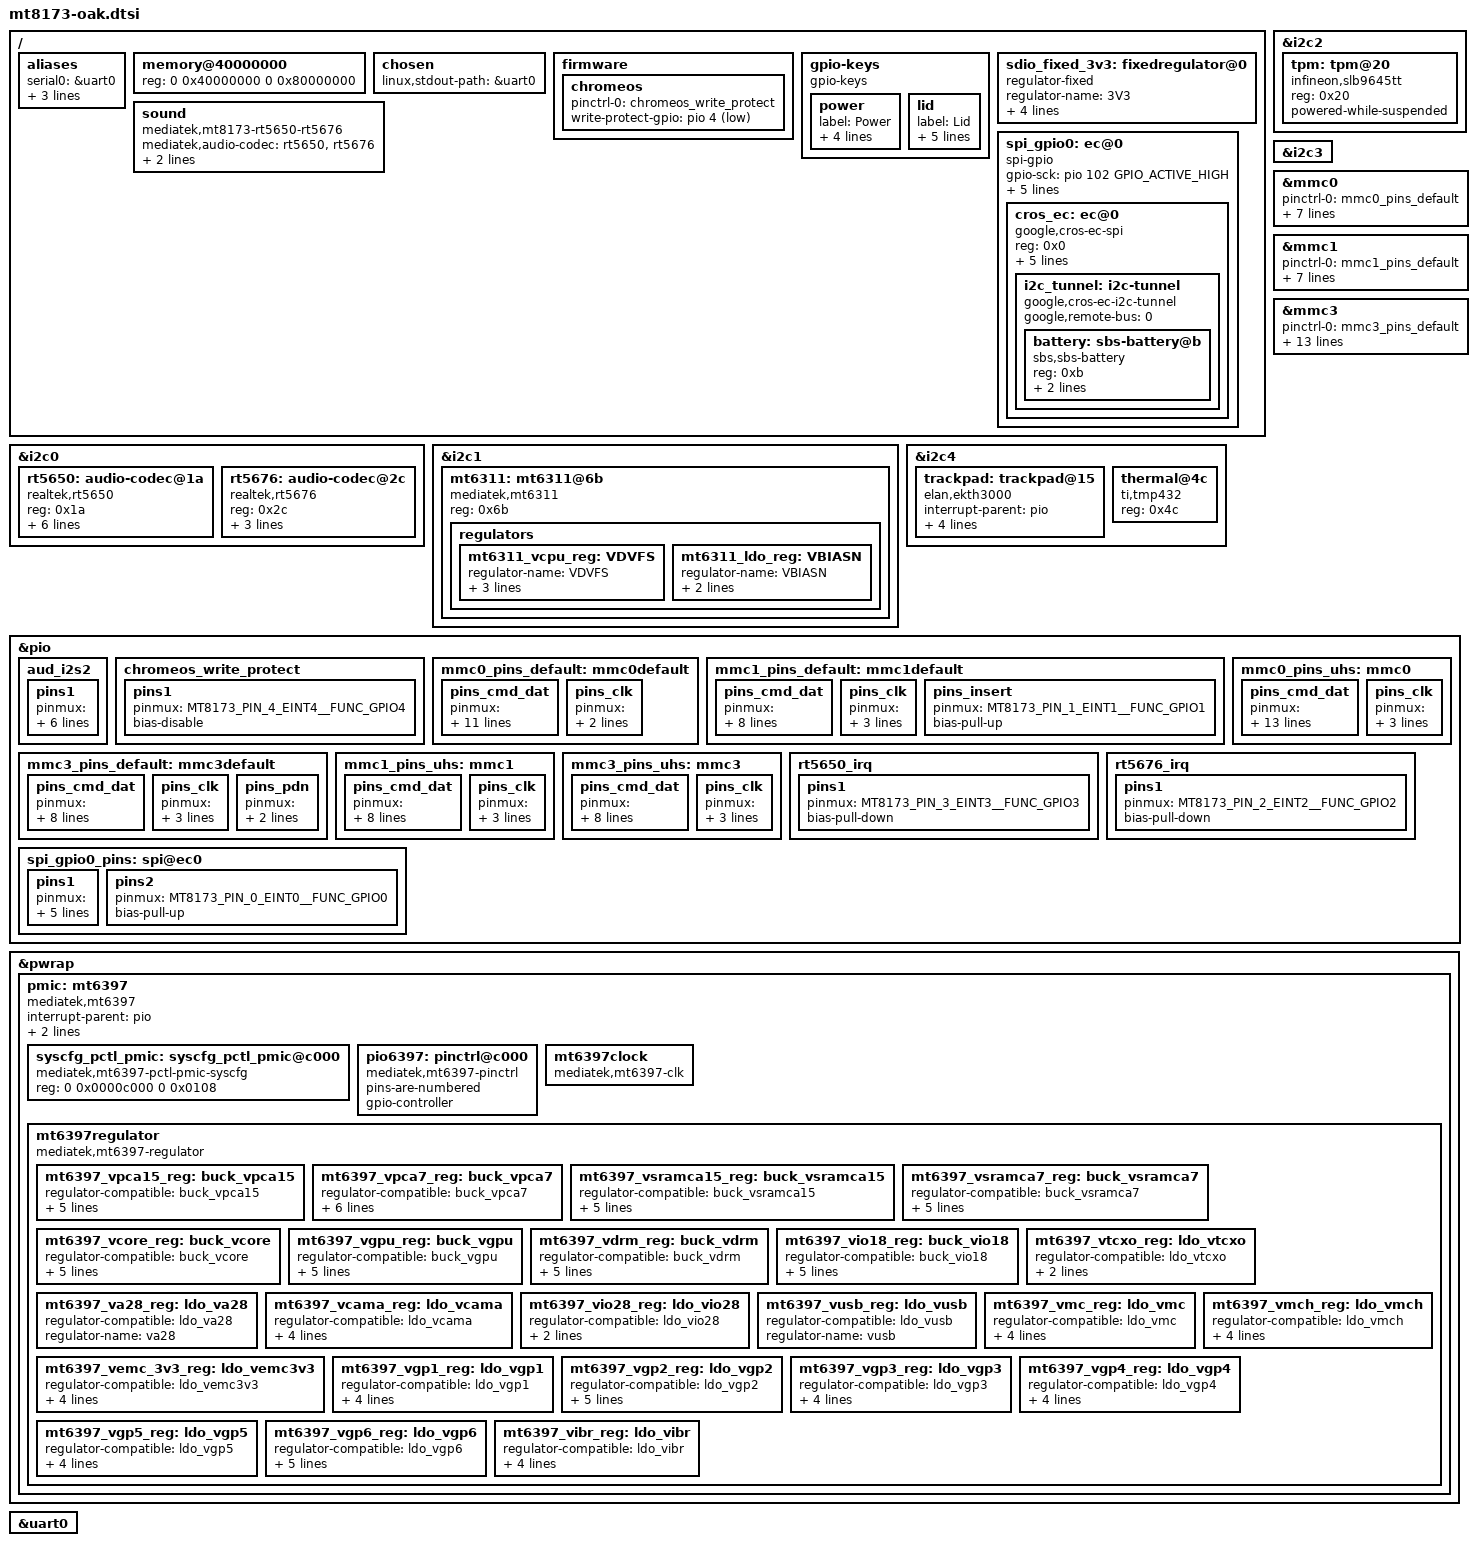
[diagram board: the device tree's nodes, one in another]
/*
 * This program is free software; you can redistribute it and/or modify
 * it under the terms of the GNU General Public License version 2 as
 * published by the Free Software Foundation.
 *
 * This program is distributed in the hope that it will be useful,
 * but WITHOUT ANY WARRANTY; without even the implied warranty of
 * MERCHANTABILITY or FITNESS FOR A PARTICULAR PURPOSE.  See the
 * GNU General Public License for more details.
 */

#include <dt-bindings/input/input.h>
#include <dt-bindings/gpio/gpio.h>
#include "mt8173.dtsi"
#include "mt8173-pinfunc.h"

/ {
	aliases {
		serial0 = &uart0;
		serial1 = &uart1;
		serial2 = &uart2;
		serial3 = &uart3;
	};

	memory@40000000 {
		device_type = "memory";
		reg = <0 0x40000000 0 0x80000000>;
	};

	chosen {
		linux,stdout-path = &uart0;
	};

	firmware {
		chromeos {
			pinctrl-names = "default";
			pinctrl-0 = <&chromeos_write_protect>;
			write-protect-gpio = <&pio 4 GPIO_ACTIVE_LOW>;
		};
	};

	gpio-keys {
		compatible = "gpio-keys";

		power {
			label = "Power";
			gpios = <&pio 14 GPIO_ACTIVE_HIGH>;
			linux,code = <KEY_POWER>;
			debounce-interval = <1>;
			gpio-key,wakeup;
		};

		lid {
			label = "Lid";
			gpios = <&pio 12 GPIO_ACTIVE_LOW>;
			linux,code = <0>; /* SW_LID */
			linux,input-type = <5>; /* EV_SW */
			debounce-interval = <1>;
			gpio-key,wakeup;
		};
	};

	sdio_fixed_3v3: fixedregulator@0 {
		compatible = "regulator-fixed";
		regulator-name = "3V3";
		regulator-min-microvolt = <3300000>;
		regulator-max-microvolt = <3300000>;
		gpio = <&pio 100 0>;
		enable-active-high;
	};

	sound {
		compatible = "mediatek,mt8173-rt5650-rt5676";
		mediatek,audio-codec = <&rt5650 &rt5676>;
		mediatek,platform = <&afe>;
		pinctrl-names = "default";
		pinctrl-0 = <&aud_i2s2>;
	};

	spi_gpio0: ec@0 {
		compatible = "spi-gpio";
		#address-cells = <0x1>;
		#size-cells = <0>;
		gpio-sck = <&pio 102 GPIO_ACTIVE_HIGH>;
		gpio-miso = <&pio 103 GPIO_ACTIVE_HIGH>;
		gpio-mosi = <&pio 104 GPIO_ACTIVE_HIGH>;
		cs-gpios = <&pio 105 GPIO_ACTIVE_HIGH>;
		num-chipselects = <1>;
		pinctrl-names = "default";
		pinctrl-0 = <&spi_gpio0_pins>;
		status = "okay";

		cros_ec: ec@0 {
			compatible = "google,cros-ec-spi";
			reg = <0x0>;
			spi-max-frequency = <18000000>;
			interrupt-parent = <&pio>;
			interrupts = <0 IRQ_TYPE_LEVEL_LOW>;
			google,cros-ec-spi-msg-delay = <500>;
			google,cros-ec-spi-pre-delay = <500>;

			i2c_tunnel: i2c-tunnel {
				compatible = "google,cros-ec-i2c-tunnel";
				google,remote-bus = <0>;
				#address-cells = <1>;
				#size-cells = <0>;
			};
		};
	};
};

&i2c0 {
	status = "okay";

	rt5650: audio-codec@1a {
		compatible = "realtek,rt5650";
		reg = <0x1a>;
		avdd-supply = <&mt6397_vgp1_reg>;
		cpvdd-supply = <&mt6397_vcama_reg>;
		interrupt-parent = <&pio>;
		interrupts = <3 IRQ_TYPE_EDGE_BOTH>;
		pinctrl-names = "default";
		pinctrl-0 = <&rt5650_irq>;
		realtek,jd-mode = <3>;
	};

	rt5676: audio-codec@2c {
		compatible = "realtek,rt5676";
		reg = <0x2c>;
		interrupt-parent = <&pio>;
		interrupts = <2 IRQ_TYPE_EDGE_BOTH>;
		pinctrl-names = "default";
		pinctrl-0 = <&rt5676_irq>;
	};
};

&i2c1 {
	status = "okay";

	mt6311: mt6311@6b {
		compatible = "mediatek,mt6311";
		reg = <0x6b>;

		regulators {
			mt6311_vcpu_reg: VDVFS {
				regulator-name = "VDVFS";
				regulator-min-microvolt = < 600000>;
				regulator-max-microvolt = <1400000>;
				regulator-ramp-delay = <10000>;
			};
			mt6311_ldo_reg: VBIASN {
				regulator-name = "VBIASN";
				regulator-min-microvolt = <200000>;
				regulator-max-microvolt = <800000>;
			};
		};
	};
};

&i2c2 {
	status = "okay";

	tpm: tpm@20 {
		compatible = "infineon,slb9645tt";
		reg = <0x20>;
		powered-while-suspended;
	};
};

&i2c3 {
	status = "okay";
};

&i2c4 {
	status = "okay";

	trackpad: trackpad@15 {
		compatible = "elan,ekth3000";
		interrupt-parent = <&pio>;
		interrupts = <124 IRQ_TYPE_LEVEL_LOW>;
		reg = <0x15>;
		vcc-supply = <&mt6397_vgp6_reg>;
		wakeup-source;
	};

	thermal@4c {
		compatible = "ti,tmp432";
		reg = <0x4c>;
	};
};

&i2c_tunnel {
	battery: sbs-battery@b {
		compatible = "sbs,sbs-battery";
		reg = <0xb>;
		sbs,i2c-retry-count = <2>;
		sbs,poll-retry-count = <1>;
	};
};

&mmc0 {
	status = "okay";
	pinctrl-names = "default", "state_uhs";
	pinctrl-0 = <&mmc0_pins_default>;
	pinctrl-1 = <&mmc0_pins_uhs>;
	bus-width = <8>;
	max-frequency = <50000000>;
	cap-mmc-highspeed;
	vmmc-supply = <&mt6397_vemc_3v3_reg>;
	vqmmc-supply = <&mt6397_vio18_reg>;
	non-removable;
};

&mmc1 {
	status = "okay";
	pinctrl-names = "default", "state_uhs";
	pinctrl-0 = <&mmc1_pins_default>;
	pinctrl-1 = <&mmc1_pins_uhs>;
	bus-width = <4>;
	max-frequency = <25000000>;
	cap-sd-highspeed;
	cd-gpios = <&pio 1 GPIO_ACTIVE_HIGH>;
	vmmc-supply = <&mt6397_vmch_reg>;
	vqmmc-supply = <&mt6397_vmc_reg>;
};

&mmc3 {
	status = "okay";
	pinctrl-names = "default", "state_uhs";
	pinctrl-0 = <&mmc3_pins_default>;
	pinctrl-1 = <&mmc3_pins_uhs>;
	bus-width = <4>;
	max-frequency = <25000000>;
	cap-sd-highspeed;
	sd-uhs-sdr12;
	sd-uhs-sdr25;
	sd-uhs-sdr50;
	sd-uhs-sdr104;
	keep-power-in-suspend;
	enable-sdio-wakeup;
	vmmc-supply = <&sdio_fixed_3v3>;
	vqmmc-supply = <&mt6397_vgp3_reg>;
	non-removable;
};

&pio {
	aud_i2s2: aud_i2s2 {
		pins1 {
			pinmux = <MT8173_PIN_128_I2S0_LRCK__FUNC_I2S1_WS>,
				 <MT8173_PIN_129_I2S0_BCK__FUNC_I2S1_BCK>,
				 <MT8173_PIN_130_I2S0_MCK__FUNC_I2S1_MCK>,
				 <MT8173_PIN_131_I2S0_DATA0__FUNC_I2S1_DO_1>,
				 <MT8173_PIN_132_I2S0_DATA1__FUNC_I2S2_DI_2>;
			bias-pull-down;
		};
	};

	chromeos_write_protect: chromeos_write_protect {
		pins1 {
			pinmux = <MT8173_PIN_4_EINT4__FUNC_GPIO4>;
			bias-disable;
		};
	};

	mmc0_pins_default: mmc0default {
		pins_cmd_dat {
			pinmux = <MT8173_PIN_57_MSDC0_DAT0__FUNC_MSDC0_DAT0>,
				 <MT8173_PIN_58_MSDC0_DAT1__FUNC_MSDC0_DAT1>,
				 <MT8173_PIN_59_MSDC0_DAT2__FUNC_MSDC0_DAT2>,
				 <MT8173_PIN_60_MSDC0_DAT3__FUNC_MSDC0_DAT3>,
				 <MT8173_PIN_61_MSDC0_DAT4__FUNC_MSDC0_DAT4>,
				 <MT8173_PIN_62_MSDC0_DAT5__FUNC_MSDC0_DAT5>,
				 <MT8173_PIN_63_MSDC0_DAT6__FUNC_MSDC0_DAT6>,
				 <MT8173_PIN_64_MSDC0_DAT7__FUNC_MSDC0_DAT7>,
				 <MT8173_PIN_66_MSDC0_CMD__FUNC_MSDC0_CMD>,
				 <MT8173_PIN_68_MSDC0_RST___FUNC_MSDC0_RSTB>;
				bias-pull-up;
		};

		pins_clk {
			pinmux = <MT8173_PIN_65_MSDC0_CLK__FUNC_MSDC0_CLK>;
				bias-pull-down;
		};
	};

	mmc1_pins_default: mmc1default {
		pins_cmd_dat {
			pinmux = <MT8173_PIN_73_MSDC1_DAT0__FUNC_MSDC1_DAT0>,
				 <MT8173_PIN_74_MSDC1_DAT1__FUNC_MSDC1_DAT1>,
				 <MT8173_PIN_75_MSDC1_DAT2__FUNC_MSDC1_DAT2>,
				 <MT8173_PIN_76_MSDC1_DAT3__FUNC_MSDC1_DAT3>,
				 <MT8173_PIN_78_MSDC1_CMD__FUNC_MSDC1_CMD>;
			input-enable;
			drive-strength = <MTK_DRIVE_4mA>;
			bias-pull-up = <MTK_PUPD_SET_R1R0_10>;
		};

		pins_clk {
			pinmux = <MT8173_PIN_77_MSDC1_CLK__FUNC_MSDC1_CLK>;
			bias-pull-down;
			drive-strength = <MTK_DRIVE_4mA>;
		};

		pins_insert {
			pinmux = <MT8173_PIN_1_EINT1__FUNC_GPIO1>;
			bias-pull-up;
		};
	};

	mmc3_pins_default: mmc3default {
		pins_cmd_dat {
			pinmux = <MT8173_PIN_22_MSDC3_DAT0__FUNC_MSDC3_DAT0>,
				 <MT8173_PIN_23_MSDC3_DAT1__FUNC_MSDC3_DAT1>,
				 <MT8173_PIN_24_MSDC3_DAT2__FUNC_MSDC3_DAT2>,
				 <MT8173_PIN_25_MSDC3_DAT3__FUNC_MSDC3_DAT3>,
				 <MT8173_PIN_27_MSDC3_CMD__FUNC_MSDC3_CMD>;
			input-enable;
			drive-strength = <MTK_DRIVE_4mA>;
			bias-pull-up = <MTK_PUPD_SET_R1R0_10>;
		};

		pins_clk {
			pinmux = <MT8173_PIN_26_MSDC3_CLK__FUNC_MSDC3_CLK>;
			bias-pull-down;
			drive-strength = <MTK_DRIVE_4mA>;
		};

		pins_pdn {
			pinmux = <MT8173_PIN_100_MSDC2_DAT0__FUNC_GPIO100>;
			output-high;
		};
	};

	mmc0_pins_uhs: mmc0 {
		pins_cmd_dat {
			pinmux = <MT8173_PIN_57_MSDC0_DAT0__FUNC_MSDC0_DAT0>,
				 <MT8173_PIN_58_MSDC0_DAT1__FUNC_MSDC0_DAT1>,
				 <MT8173_PIN_59_MSDC0_DAT2__FUNC_MSDC0_DAT2>,
				 <MT8173_PIN_60_MSDC0_DAT3__FUNC_MSDC0_DAT3>,
				 <MT8173_PIN_61_MSDC0_DAT4__FUNC_MSDC0_DAT4>,
				 <MT8173_PIN_62_MSDC0_DAT5__FUNC_MSDC0_DAT5>,
				 <MT8173_PIN_63_MSDC0_DAT6__FUNC_MSDC0_DAT6>,
				 <MT8173_PIN_64_MSDC0_DAT7__FUNC_MSDC0_DAT7>,
				 <MT8173_PIN_68_MSDC0_RST___FUNC_MSDC0_RSTB>,
				 <MT8173_PIN_66_MSDC0_CMD__FUNC_MSDC0_CMD>;
			input-enable;
			drive-strength = <MTK_DRIVE_2mA>;
			bias-pull-up = <MTK_PUPD_SET_R1R0_01>;
		};

		pins_clk {
			pinmux = <MT8173_PIN_65_MSDC0_CLK__FUNC_MSDC0_CLK>;
			drive-strength = <MTK_DRIVE_2mA>;
			bias-pull-down = <MTK_PUPD_SET_R1R0_01>;
		};
	};

	mmc1_pins_uhs: mmc1 {
		pins_cmd_dat {
			pinmux = <MT8173_PIN_73_MSDC1_DAT0__FUNC_MSDC1_DAT0>,
				 <MT8173_PIN_74_MSDC1_DAT1__FUNC_MSDC1_DAT1>,
				 <MT8173_PIN_75_MSDC1_DAT2__FUNC_MSDC1_DAT2>,
				 <MT8173_PIN_76_MSDC1_DAT3__FUNC_MSDC1_DAT3>,
				 <MT8173_PIN_78_MSDC1_CMD__FUNC_MSDC1_CMD>;
			input-enable;
			drive-strength = <MTK_DRIVE_4mA>;
			bias-pull-up = <MTK_PUPD_SET_R1R0_10>;
		};

		pins_clk {
			pinmux = <MT8173_PIN_77_MSDC1_CLK__FUNC_MSDC1_CLK>;
			drive-strength = <MTK_DRIVE_4mA>;
			bias-pull-down = <MTK_PUPD_SET_R1R0_10>;
		};
	};

	mmc3_pins_uhs: mmc3 {
		pins_cmd_dat {
			pinmux = <MT8173_PIN_22_MSDC3_DAT0__FUNC_MSDC3_DAT0>,
				 <MT8173_PIN_23_MSDC3_DAT1__FUNC_MSDC3_DAT1>,
				 <MT8173_PIN_24_MSDC3_DAT2__FUNC_MSDC3_DAT2>,
				 <MT8173_PIN_25_MSDC3_DAT3__FUNC_MSDC3_DAT3>,
				 <MT8173_PIN_27_MSDC3_CMD__FUNC_MSDC3_CMD>;
			input-enable;
			drive-strength = <MTK_DRIVE_4mA>;
			bias-pull-up = <MTK_PUPD_SET_R1R0_10>;
		};

		pins_clk {
			pinmux = <MT8173_PIN_26_MSDC3_CLK__FUNC_MSDC3_CLK>;
			drive-strength = <MTK_DRIVE_4mA>;
			bias-pull-down = <MTK_PUPD_SET_R1R0_10>;
		};
	};

	rt5650_irq: rt5650_irq {
		pins1 {
			pinmux = <MT8173_PIN_3_EINT3__FUNC_GPIO3>;
			bias-pull-down;
		};
	};

	rt5676_irq: rt5676_irq {
		pins1 {
			pinmux = <MT8173_PIN_2_EINT2__FUNC_GPIO2>;
			bias-pull-down;
		};
	};

	spi_gpio0_pins: spi@ec0 {
		pins1 {
			pinmux = <MT8173_PIN_102_MSDC2_DAT2__FUNC_GPIO102>,
				 <MT8173_PIN_103_MSDC2_DAT3__FUNC_GPIO103>,
				 <MT8173_PIN_104_MSDC2_CLK__FUNC_GPIO104>,
				 <MT8173_PIN_105_MSDC2_CMD__FUNC_GPIO105>;
			bias-disable;
		};

		pins2 {
			pinmux = <MT8173_PIN_0_EINT0__FUNC_GPIO0>;
			bias-pull-up;
		};
	};
};

&pwrap {
	pmic: mt6397 {
		compatible = "mediatek,mt6397";
		#address-cells = <1>;
		#size-cells = <1>;
		interrupt-parent = <&pio>;
		interrupts = <11 IRQ_TYPE_LEVEL_HIGH>;
		interrupt-controller;
		#interrupt-cells = <2>;

		syscfg_pctl_pmic: syscfg_pctl_pmic@c000 {
			compatible = "mediatek,mt6397-pctl-pmic-syscfg",
				     "syscon";
			reg = <0 0x0000c000 0 0x0108>;
		};

		pio6397: pinctrl@c000 {
			compatible = "mediatek,mt6397-pinctrl";
			pins-are-numbered;
			gpio-controller;
			#gpio-cells = <2>;
		};

		mt6397clock: mt6397clock {
			compatible = "mediatek,mt6397-clk";
			#clock-cells = <1>;
		};

		mt6397regulator: mt6397regulator {
			compatible = "mediatek,mt6397-regulator";

			mt6397_vpca15_reg: buck_vpca15 {
				regulator-compatible = "buck_vpca15";
				regulator-name = "vpca15";
				regulator-min-microvolt = < 700000>;
				regulator-max-microvolt = <1350000>;
				regulator-ramp-delay = <12500>;
				regulator-always-on;
			};

			mt6397_vpca7_reg: buck_vpca7 {
				regulator-compatible = "buck_vpca7";
				regulator-name = "vpca7";
				regulator-min-microvolt = < 700000>;
				regulator-max-microvolt = <1350000>;
				regulator-ramp-delay = <12500>;
				regulator-enable-ramp-delay = <115>;
				regulator-always-on;
			};

			mt6397_vsramca15_reg: buck_vsramca15 {
				regulator-compatible = "buck_vsramca15";
				regulator-name = "vsramca15";
				regulator-min-microvolt = < 700000>;
				regulator-max-microvolt = <1350000>;
				regulator-ramp-delay = <12500>;
				regulator-always-on;
			};

			mt6397_vsramca7_reg: buck_vsramca7 {
				regulator-compatible = "buck_vsramca7";
				regulator-name = "vsramca7";
				regulator-min-microvolt = < 700000>;
				regulator-max-microvolt = <1350000>;
				regulator-ramp-delay = <12500>;
				regulator-always-on;
			};

			mt6397_vcore_reg: buck_vcore {
				regulator-compatible = "buck_vcore";
				regulator-name = "vcore";
				regulator-min-microvolt = < 700000>;
				regulator-max-microvolt = <1350000>;
				regulator-ramp-delay = <12500>;
				regulator-always-on;
			};

			mt6397_vgpu_reg: buck_vgpu {
				regulator-compatible = "buck_vgpu";
				regulator-name = "vgpu";
				regulator-min-microvolt = < 700000>;
				regulator-max-microvolt = <1350000>;
				regulator-ramp-delay = <12500>;
				regulator-enable-ramp-delay = <115>;
			};

			mt6397_vdrm_reg: buck_vdrm {
				regulator-compatible = "buck_vdrm";
				regulator-name = "vdrm";
				regulator-min-microvolt = <1200000>;
				regulator-max-microvolt = <1400000>;
				regulator-ramp-delay = <12500>;
				regulator-always-on;
			};

			mt6397_vio18_reg: buck_vio18 {
				regulator-compatible = "buck_vio18";
				regulator-name = "vio18";
				regulator-min-microvolt = <1620000>;
				regulator-max-microvolt = <1980000>;
				regulator-ramp-delay = <12500>;
				regulator-always-on;
			};

			mt6397_vtcxo_reg: ldo_vtcxo {
				regulator-compatible = "ldo_vtcxo";
				regulator-name = "vtcxo";
				regulator-always-on;
			};

			mt6397_va28_reg: ldo_va28 {
				regulator-compatible = "ldo_va28";
				regulator-name = "va28";
			};

			mt6397_vcama_reg: ldo_vcama {
				regulator-compatible = "ldo_vcama";
				regulator-name = "vcama";
				regulator-min-microvolt = <1800000>;
				regulator-max-microvolt = <1800000>;
				regulator-enable-ramp-delay = <218>;
			};

			mt6397_vio28_reg: ldo_vio28 {
				regulator-compatible = "ldo_vio28";
				regulator-name = "vio28";
				regulator-always-on;
			};

			mt6397_vusb_reg: ldo_vusb {
				regulator-compatible = "ldo_vusb";
				regulator-name = "vusb";
			};

			mt6397_vmc_reg: ldo_vmc {
				regulator-compatible = "ldo_vmc";
				regulator-name = "vmc";
				regulator-min-microvolt = <1800000>;
				regulator-max-microvolt = <3300000>;
				regulator-enable-ramp-delay = <218>;
			};

			mt6397_vmch_reg: ldo_vmch {
				regulator-compatible = "ldo_vmch";
				regulator-name = "vmch";
				regulator-min-microvolt = <3000000>;
				regulator-max-microvolt = <3300000>;
				regulator-enable-ramp-delay = <218>;
			};

			mt6397_vemc_3v3_reg: ldo_vemc3v3 {
				regulator-compatible = "ldo_vemc3v3";
				regulator-name = "vemc_3v3";
				regulator-min-microvolt = <3000000>;
				regulator-max-microvolt = <3300000>;
				regulator-enable-ramp-delay = <218>;
			};

			mt6397_vgp1_reg: ldo_vgp1 {
				regulator-compatible = "ldo_vgp1";
				regulator-name = "vcamd";
				regulator-min-microvolt = <1800000>;
				regulator-max-microvolt = <1800000>;
				regulator-enable-ramp-delay = <240>;
			};

			mt6397_vgp2_reg: ldo_vgp2 {
				regulator-compatible = "ldo_vgp2";
				regulator-name = "vcamio";
				regulator-min-microvolt = <1800000>;
				regulator-max-microvolt = <1800000>;
				regulator-enable-ramp-delay = <218>;
				regulator-always-on;
			};

			mt6397_vgp3_reg: ldo_vgp3 {
				regulator-compatible = "ldo_vgp3";
				regulator-name = "vcamaf";
				regulator-min-microvolt = <1620000>;
				regulator-max-microvolt = <1980000>;
				regulator-enable-ramp-delay = <218>;
			};

			mt6397_vgp4_reg: ldo_vgp4 {
				regulator-compatible = "ldo_vgp4";
				regulator-name = "vgp4";
				regulator-min-microvolt = <1200000>;
				regulator-max-microvolt = <3300000>;
				regulator-enable-ramp-delay = <218>;
			};

			mt6397_vgp5_reg: ldo_vgp5 {
				regulator-compatible = "ldo_vgp5";
				regulator-name = "vgp5";
				regulator-min-microvolt = <1200000>;
				regulator-max-microvolt = <3000000>;
				regulator-enable-ramp-delay = <218>;
			};

			mt6397_vgp6_reg: ldo_vgp6 {
				regulator-compatible = "ldo_vgp6";
				regulator-name = "vgp6";
				regulator-min-microvolt = <3300000>;
				regulator-max-microvolt = <3300000>;
				regulator-enable-ramp-delay = <218>;
				regulator-always-on;
			};

			mt6397_vibr_reg: ldo_vibr {
				regulator-compatible = "ldo_vibr";
				regulator-name = "vibr";
				regulator-min-microvolt = <1300000>;
				regulator-max-microvolt = <3300000>;
				regulator-enable-ramp-delay = <218>;
			};
		};
	};
};

&uart0 {
	status = "okay";
};

#include "../../../../arm/boot/dts/cros-ec-keyboard.dtsi"
